AUTOSAR XML (schema 4-0-3)
standard types defined: Boolean, UInt16, UInt8
package /AUTOSAR_Platform/DataConstrs
  range DC_Boolean: raw 0..1
  range DC_UInt16: raw 0..65535
package /PATAC/MSM/ComponentTypes
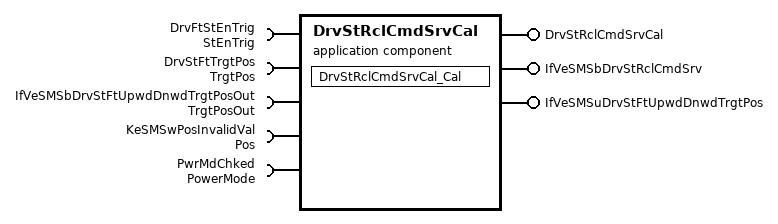
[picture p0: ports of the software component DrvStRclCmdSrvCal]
  application sw component type DrvStRclCmdSrvCal
    provide port DrvStRclCmdSrvCal: server-com-spec{operation=Cal, queue-length=1}, provided-interface=DrvStRclCmdSrvCal
    provide port IfVeSMSbDrvStRclCmdSrv: nonqueued-sender-com-spec{data-element=IfVeSMSbDrvStRclCmdSrv/Val, init-value=0}, provided-interface=IfVeSMSbDrvStRclCmdSrv
    provide port IfVeSMSuDrvStFtUpwdDnwdTrgtPos: nonqueued-sender-com-spec{data-element=IfVeSMSuDrvStFtUpwdDnwdTrgtPos/Val, init-value=4095}, provided-interface=IfVeSMSuDrvStFtUpwdDnwdTrgtPos
    5 x require port:
      DrvFtStEnTrig: nonqueued-receiver-com-spec{data-element=StEnTrig/Val, filter=data-filter-type=ALWAYS, init-value=0}, required-interface=StEnTrig
      DrvStFtTrgtPos: nonqueued-receiver-com-spec{data-element=TrgtPos/Val, filter=data-filter-type=ALWAYS, init-value=4095}, required-interface=TrgtPos
      IfVeSMSbDrvStFtUpwdDnwdTrgtPosOut: nonqueued-receiver-com-spec{data-element=TrgtPosOut/Val, filter=data-filter-type=ALWAYS, init-value=0}, required-interface=TrgtPosOut
      KeSMSwPosInvalidVal: parameter-require-com-spec{init-value=4095, parameter=Val}, required-interface=Pos
      PwrMdChked: nonqueued-receiver-com-spec{data-element=PowerMode/Val, filter=data-filter-type=ALWAYS, init-value=0}, required-interface=PowerMode
    behavior DrvStRclCmdSrvCal_InternalBehavior
      operation invoked event OIT_DrvStRclCmdSrvCal_Cal_DrvStRclCmdSrvCal_Cal: start-on-event=DrvStRclCmdSrvCal_Cal, operation=DrvStRclCmdSrvCal.Cal
      runnable DrvStRclCmdSrvCal_Cal
        data-receive-point-by-arguments:
          4 x access:
            REC_DrvFtStEnTrig_Val: accessed-variable=DrvFtStEnTrig.Val
            REC_DrvStFtTrgtPos_Val: accessed-variable=DrvStFtTrgtPos.Val
            REC_IfVeSMSbDrvStFtUpwdDnwdTrgtPosOut_Val: accessed-variable=IfVeSMSbDrvStFtUpwdDnwdTrgtPosOut.Val
            REC_PwrMdChked_Val: accessed-variable=PwrMdChked.Val
        data-send-points:
          access SEND_IfVeSMSbDrvStRclCmdSrv_Val: accessed-variable=IfVeSMSbDrvStRclCmdSrv.Val
          access SEND_IfVeSMSuDrvStFtUpwdDnwdTrgtPos_Val: accessed-variable=IfVeSMSuDrvStFtUpwdDnwdTrgtPos.Val
        parameter access PA_KeSMSwPosInvalidVal_Val: accessed-parameter=KeSMSwPosInvalidVal.Val
  swc implementation DrvStRclCmdSrvCal_Implementation: behavior=DrvStRclCmdSrvCal_InternalBehavior
    code-descriptors:
      code Default: artifact-descriptors=autosar-engineering-object={short-label=Default, category=SWSRC}
package /PATAC/MSM/ModeAdjust/CalPortInterface
  parameter interface Pos
    parameter data prototype Val: sw-calibration-access=READ-WRITE, type=UInt16
package /PATAC/MSM/ModeAdjust/DataType
  impl type PowerMode1: category=VALUE, base-type=UInt8, sw-calibration-access=READ-ONLY, compu {0=PowerMode_Off, 1=PowerMode_Acc, 2=PowerMode_Run, 3=PowerMode_Crank, 4=PowerMode_Invalid}, type-emitter=RTE
package /PATAC/MSM/ModeAdjust/Interfaces
  sender receiver interface IfVeSMSbDrvStRclCmdSrv: invalidation-policy{data-element=IfVeSMSbDrvStRclCmdSrv/Val, handle-invalid=DONT-INVALIDATE}
    data Val: type=Boolean
package /PATAC/MSM/ModeAdjust/PortInterface
  client server interface DrvStRclCmdSrvCal
    operation Cal
  sender receiver interface PowerMode: invalidation-policy{data-element=PowerMode/Val, handle-invalid=DONT-INVALIDATE}
    data Val: type=PowerMode1
  sender receiver interface StEnTrig: invalidation-policy{data-element=StEnTrig/Val, handle-invalid=DONT-INVALIDATE}
    data Val: type=Boolean
  sender receiver interface TrgtPosOut: invalidation-policy{data-element=TrgtPosOut/Val, handle-invalid=DONT-INVALIDATE}
    data Val: type=Boolean
package /PATAC/MSM/PortInterfaces
  sender receiver interface IfVeSMSuDrvStFtUpwdDnwdTrgtPos: invalidation-policy{data-element=IfVeSMSuDrvStFtUpwdDnwdTrgtPos/Val, handle-invalid=DONT-INVALIDATE}
    data Val: type=UInt16
  sender receiver interface TrgtPos: invalidation-policy{data-element=TrgtPos/Val, handle-invalid=DONT-INVALIDATE}
    data Val: type=UInt16
